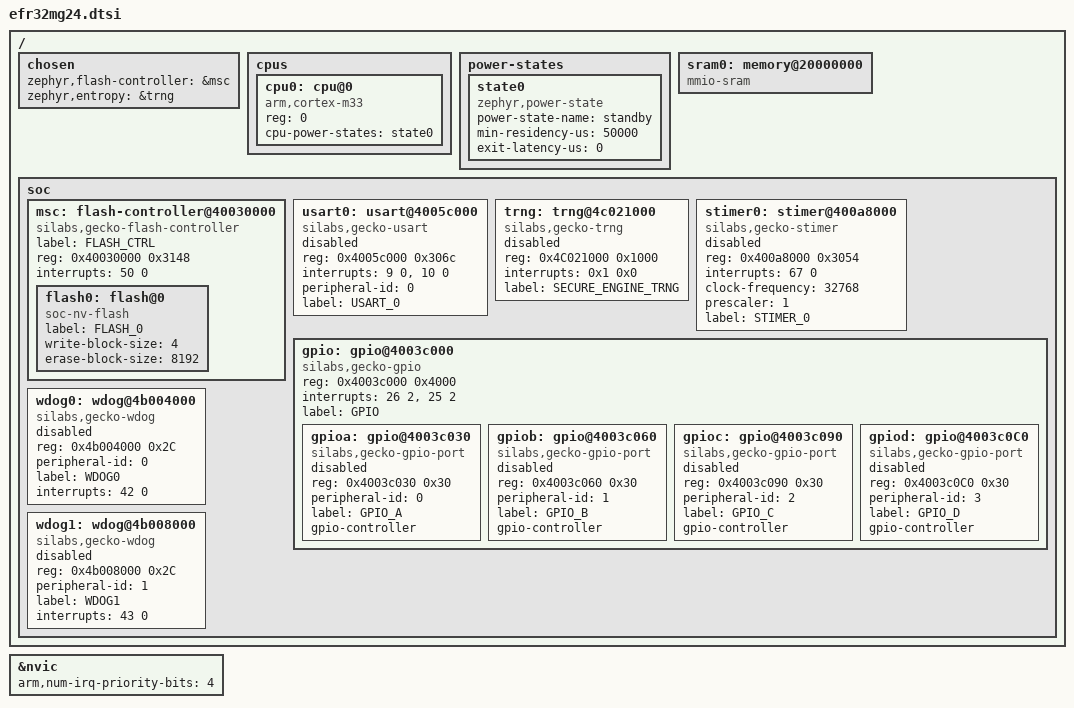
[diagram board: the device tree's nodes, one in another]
/*
 * Copyright (c) 2020 TriaGnoSys GmbH
 *
 * SPDX-License-Identifier: Apache-2.0
 */

#include <arm/armv8-m.dtsi>
#include <dt-bindings/gpio/gpio.h>
#include <dt-bindings/i2c/i2c.h>
#include "gpio_gecko.h"

/ {
	chosen {
		zephyr,flash-controller = &msc;
		zephyr,entropy = &trng;
	};

 	cpus {
 		#address-cells = <1>;
		#size-cells = <0>;
		
 		cpu0: cpu@0 {
			device_type = "cpu";
			compatible = "arm,cortex-m33";
			reg = <0>;
			cpu-power-states = <&state0>;
 		};
 	};
 
 	power-states {
 		state0: state0 {
 			compatible = "zephyr,power-state";
 			power-state-name = "standby";
 			min-residency-us = <50000>;
 			exit-latency-us = <0>;
 		};
 	};

	sram0: memory@20000000 {
		device_type = "memory";
		compatible = "mmio-sram";
	};

	soc {
		msc: flash-controller@40030000 {
			compatible = "silabs,gecko-flash-controller";
			label = "FLASH_CTRL";
			reg = <0x40030000 0x3148>;
			interrupts = <50 0>;

			#address-cells = <1>;
			#size-cells = <1>;

			flash0: flash@0 {
				compatible = "soc-nv-flash";
				label = "FLASH_0";
				write-block-size = <4>;
				erase-block-size = <8192>;
			};
		};

		usart0: usart@4005c000 { /* USART0 */
			compatible = "silabs,gecko-usart";
			reg = <0x4005c000 0x306c>;
			interrupts = <9 0>, <10 0>;
			interrupt-names = "rx", "tx";
			peripheral-id = <0>;
			status = "disabled";
			label = "USART_0";
		};
		
		trng: trng@4c021000 {
			compatible = "silabs,gecko-trng";
			reg = < 0x4C021000 0x1000 >;
			status = "disabled";
			interrupts = < 0x1 0x0 >;
			label = "SECURE_ENGINE_TRNG";
		};
		
		stimer0: stimer@400a8000 {
			compatible = "silabs,gecko-stimer";
			reg = <0x400a8000 0x3054>;
			interrupts = <67 0>;
			clock-frequency = <32768>;
			prescaler = <1>;
			status = "disabled";
			label = "STIMER_0";
		};

		gpio: gpio@4003c000 {
			compatible = "silabs,gecko-gpio";
			reg = <0x4003c000 0x4000>;
			interrupts = <26 2>, <25 2>;
			interrupt-names = "GPIO_EVEN", "GPIO_ODD";
			label = "GPIO";

			ranges;
			#address-cells = <1>;
			#size-cells = <1>;

			gpioa: gpio@4003c030 {
				compatible = "silabs,gecko-gpio-port";
				reg = <0x4003c030 0x30>;
				peripheral-id = <0>;
				label = "GPIO_A";
				gpio-controller;
				#gpio-cells = <2>;
				status = "disabled";
			};

			gpiob: gpio@4003c060 {
				compatible = "silabs,gecko-gpio-port";
				reg = <0x4003c060 0x30>;
				peripheral-id = <1>;
				label = "GPIO_B";
				gpio-controller;
				#gpio-cells = <2>;
				status = "disabled";
			};

			gpioc: gpio@4003c090 {
				compatible = "silabs,gecko-gpio-port";
				reg = <0x4003c090 0x30>;
				peripheral-id = <2>;
				label = "GPIO_C";
				gpio-controller;
				#gpio-cells = <2>;
				status = "disabled";
			};

			gpiod: gpio@4003c0C0 {
				compatible = "silabs,gecko-gpio-port";
				reg = <0x4003c0C0 0x30>;
				peripheral-id = <3>;
				label = "GPIO_D";
				gpio-controller;
				#gpio-cells = <2>;
				status = "disabled";
			};
		};

		wdog0: wdog@4b004000 {
			compatible = "silabs,gecko-wdog";
			reg = <0x4b004000 0x2C>;
			peripheral-id = <0>;
			label = "WDOG0";
			interrupts = <42 0>;
			status = "disabled";
		};

		wdog1: wdog@4b008000 {
			compatible = "silabs,gecko-wdog";
			reg = <0x4b008000 0x2C>;
			peripheral-id = <1>;
			label = "WDOG1";
			interrupts = <43 0>;
			status = "disabled";
		};
	};
};

&nvic {
	arm,num-irq-priority-bits = <4>;
};
